# GD32F20x register map
File version: 1.0
CPU: CM3 r2p1, little endian, no MPU, no FPU, 4 interrupt priority bits
Registers are 32-bit, read-write, reset 0x0 unless marked. A register's access mark holds for its fields unless they carry their own. Offsets are from the block's base; [hi:lo] are bit positions; {n}, {i} and the like mark numbered series.

## TIMER1 — General-purpose-timers
Base 0x40000000
Same registers: TIMER2 0x40000400, TIMER3 0x40000800, TIMER4 0x40000C00
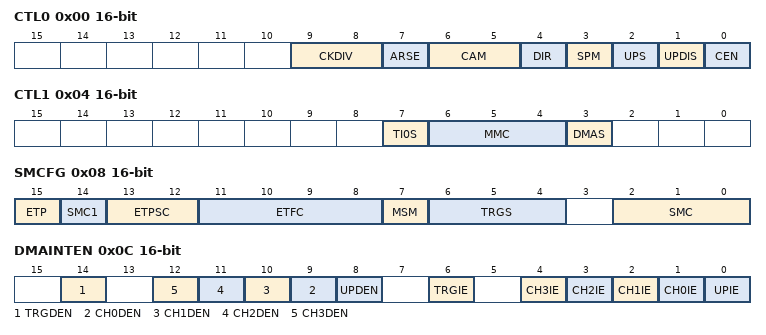
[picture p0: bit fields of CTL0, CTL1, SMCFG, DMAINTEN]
0x00 CTL0 16-bit — control register 0
  [9:8] CKDIV — Clock division
  [7] ARSE — Auto-reload shadow enable
  [6:5] CAM — Counter aligns mode selection
  [4] DIR — Direction
  [3] SPM — Single pulse mode
  [2] UPS — Update source
  [1] UPDIS — Update disable
  [0] CEN — Counter enable
0x04 CTL1 16-bit — control register 1
  [7] TI0S — Channel 0 trigger input selection
  [6:4] MMC — Master mode control
  [3] DMAS — DMA request source selection
0x08 SMCFG 16-bit — slave mode control register
  [15] ETP — External trigger polarity
  [14] SMC1 — Part of SMC for enable External clock mode1
  [13:12] ETPSC — External trigger prescaler
  [11:8] ETFC — External trigger filter control
  [7] MSM — Master-slave mode
  [6:4] TRGS — Trigger selection
  [2:0] SMC — Slave mode control
0x0C DMAINTEN 16-bit — DMA/Interrupt enable register
  [14] TRGDEN — Trigger DMA request enable
  [n+9] CH{n}DEN (n=0..3) — Channel {n} capture/compare DMA request enable
  [8] UPDEN — Update DMA request enable
  [6] TRGIE — Trigger interrupt enable
  [n+1] CH{n}IE (n=0..3) — Channel {n} capture/compare interrupt enable
  [0] UPIE — Update interrupt enable
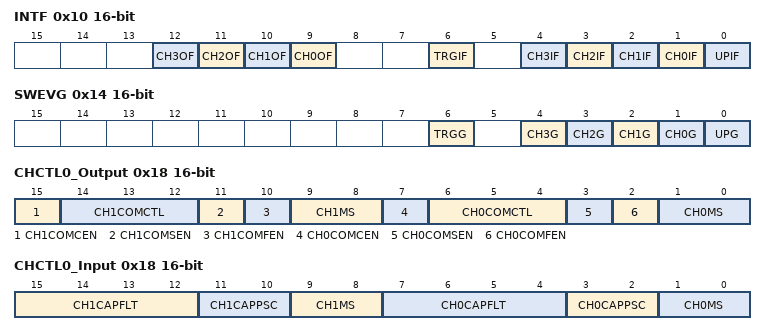
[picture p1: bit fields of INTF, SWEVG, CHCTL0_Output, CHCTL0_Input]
0x10 INTF 16-bit — interrupt flag register
  [n+9] CH{n}OF (n=0..3) — Channel {n} over capture flag
  [6] TRGIF — Trigger interrupt flag
  [4] CH3IF — Channel 3 capture/compare interrupt enable
  [3] CH2IF — Channel 2 capture/compare interrupt enable
  [2] CH1IF — Channel 1 capture/compare interrupt flag
  [1] CH0IF — Channel 0 capture/compare interrupt flag
  [0] UPIF — Update interrupt flag
0x14 SWEVG 16-bit wo — event generation register
  [6] TRGG — Trigger event generation
  [n+1] CH{n}G (n=0..3) — Channel {n} capture or compare event generation
  [0] UPG — Update generation
0x18 CHCTL0_Output 16-bit — Channel control register 0 (output mode)
  [15] CH1COMCEN — Channel 1 output compare clear enable
  [14:12] CH1COMCTL — Channel 1 compare output control
  [11] CH1COMSEN — Channel 1 output compare shadow enable
  [10] CH1COMFEN — Channel 1 output compare fast enable
  [9:8] CH1MS — Channel 1 mode selection
  [7] CH0COMCEN — Channel 0 output compare clear enable
  [6:4] CH0COMCTL — Channel 0 compare output control
  [3] CH0COMSEN — Channel 0 compare output shadow enable
  [2] CH0COMFEN — Channel 0 output compare fast enable
  [1:0] CH0MS — Channel 0 I/O mode selection
0x18 CHCTL0_Input 16-bit (alternate view of CHCTL0_Output) — Channel control register 0 (input mode)
  [15:12] CH1CAPFLT — Channel 1 input capture filter control
  [11:10] CH1CAPPSC — Channel 1 input capture prescaler
  [9:8] CH1MS — Channel 1 mode selection
  [7:4] CH0CAPFLT — Channel 0 input capture filter control
  [3:2] CH0CAPPSC — Channel 0 input capture prescaler
  [1:0] CH0MS — Channel 0 mode selection
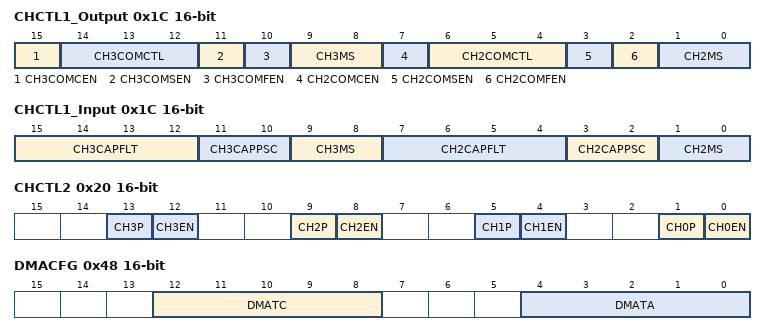
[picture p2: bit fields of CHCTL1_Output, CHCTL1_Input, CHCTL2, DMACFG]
0x1C CHCTL1_Output 16-bit — Channel control register 1 (output mode)
  [15] CH3COMCEN — Channel 3 output compare clear enable
  [14:12] CH3COMCTL — Channel 3 compare output control
  [11] CH3COMSEN — Channel 3 output compare shadow enable
  [10] CH3COMFEN — Channel 3 output compare fast enable
  [9:8] CH3MS — Channel 3 mode selection
  [7] CH2COMCEN — Channel 2 output compare clear enable
  [6:4] CH2COMCTL — Channel 2 compare output control
  [3] CH2COMSEN — Channel 2 compare output shadow enable
  [2] CH2COMFEN — Channel 2 output compare fast enable
  [1:0] CH2MS — Channel 2 I/O mode selection
0x1C CHCTL1_Input 16-bit (alternate view of CHCTL1_Output) — Channel control register 1 (input mode)
  [15:12] CH3CAPFLT — Channel 3 input capture filter control
  [11:10] CH3CAPPSC — Channel 3 input capture prescaler
  [9:8] CH3MS — Channel 3 mode selection
  [7:4] CH2CAPFLT — Channel 2 input capture filter control
  [3:2] CH2CAPPSC — Channel 2 input capture prescaler
  [1:0] CH2MS — Channel 2 mode selection
0x20 CHCTL2 16-bit — Channel control register 2
  [4n+1] CH{n}P (n=0..3) — Channel {n} capture/compare function polarity
  [4n] CH{n}EN (n=0..3) — Channel {n} capture/compare function enable
0x24 CNT 16-bit — Counter register
  [15:0] CNT — counter value
0x28 PSC 16-bit — Prescaler register
  [15:0] PSC — Prescaler value of the counter clock
0x2C CAR 16-bit — Counter auto reload register
  [15:0] CARL — Counter auto reload value
0x34 CH0CV 16-bit — Channel 0 capture/compare value register
  [15:0] CH0VAL — Capture or compare value of channel 0
0x38 CH1CV 16-bit — Channel 1 capture/compare value register
  [15:0] CH1VAL — Capture or compare value of channel1
0x3C CH2CV 16-bit — Channel 2 capture/compare value register
  [15:0] CH2VAL — Capture or compare value of channel 2
0x40 CH3CV 16-bit — Channel 3 capture/compare value register
  [15:0] CH3VAL — Capture or compare value of channel 3
0x48 DMACFG 16-bit — DMA configuration register
  [12:8] DMATC — DMA transfer count
  [4:0] DMATA — DMA transfer access start address
0x4C DMATB 16-bit — DMA transfer buffer register
  [15:0] DMATB — DMA transfer buffer

## TIMER8 — General-purpose-timers
Base 0x40014C00
Same registers: TIMER11 0x40001800
Registers as TIMER1, without CTL1, CHCTL1_Output, CHCTL1_Input, CH2CV, CH3CV, DMACFG, DMATB; these are added or differ:
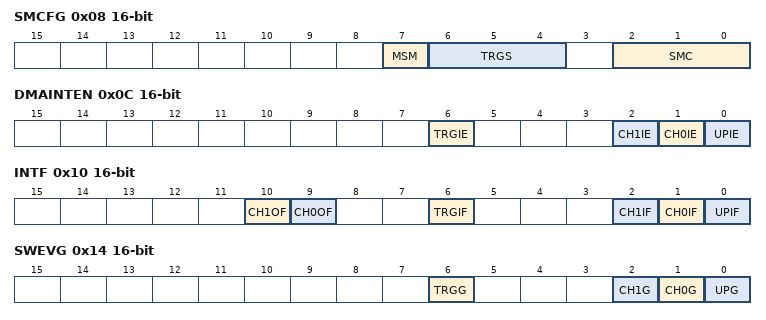
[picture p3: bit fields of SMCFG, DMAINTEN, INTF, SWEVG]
0x08 SMCFG 16-bit — slave mode configuration register
  [7] MSM — Master-slave mode
  [6:4] TRGS — Trigger selection
  [2:0] SMC — Slave mode control
0x0C DMAINTEN 16-bit — DMA and interrupt enable register
  [6] TRGIE — Trigger interrupt enable
  [2] CH1IE — Channel 1 capture/compare interrupt enable
  [1] CH0IE — Channel 0 capture/compare interrupt enable
  [0] UPIE — Update interrupt enable
0x10 INTF 16-bit — interrupt flag register
  [10] CH1OF — Channel 1 over capture flag
  [9] CH0OF — Channel 0 over capture flag
  [6] TRGIF — Trigger interrupt flag
  [2] CH1IF — Channel 1 capture/compare interrupt flag
  [1] CH0IF — Channel 0 capture/compare interrupt flag
  [0] UPIF — Update interrupt flag
0x14 SWEVG 16-bit wo — event generation register
  [6] TRGG — Trigger event generation
  [2] CH1G — Channel 1 capture or compare event generation
  [1] CH0G — Channel 0 capture or compare event generation
  [0] UPG — Update generation
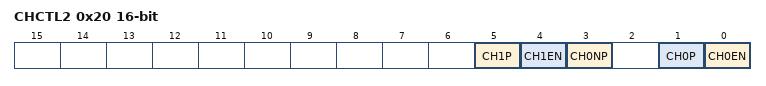
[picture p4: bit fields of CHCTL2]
0x20 CHCTL2 16-bit — Channel control register 2
  [5] CH1P — Channel 1 capture/compare function polarity
  [4] CH1EN — Channel 1 capture/compare function enable
  [3] CH0NP — Channel 0 complementary output polarity
  [1] CH0P — Channel 0 capture/compare function polarity
  [0] CH0EN — Channel 0 capture/compare function enable
0x24 CNT 16-bit — Counter register
  [15:0] CNT — current counter value
0x34 CH0CV 16-bit — Channel 0 capture/compare value register
  [15:0] CH0VAL — Capture or compare value of channel0
